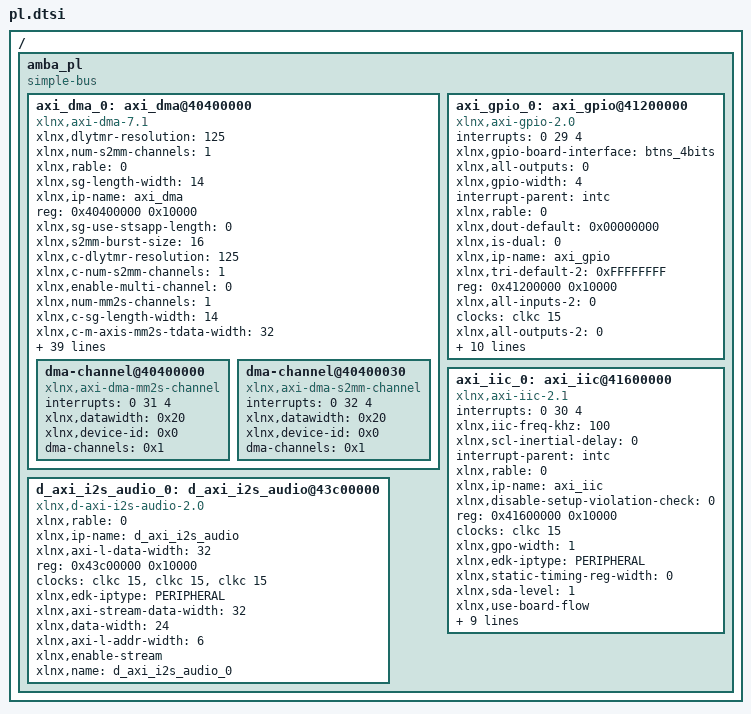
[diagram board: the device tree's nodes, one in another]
/ {
	amba_pl: amba_pl {
		ranges;
		compatible = "simple-bus";
		#address-cells = <1>;
		#size-cells = <1>;
		axi_dma_0: axi_dma@40400000 {
			xlnx,dlytmr-resolution = <125>;
			xlnx,num-s2mm-channels = <1>;
			xlnx,rable = <0>;
			xlnx,sg-length-width = <14>;
			xlnx,ip-name = "axi_dma";
			reg = <0x40400000 0x10000>;
			xlnx,sg-use-stsapp-length = <0>;
			xlnx,s2mm-burst-size = <16>;
			xlnx,c-dlytmr-resolution = <125>;
			xlnx,c-num-s2mm-channels = <1>;
			xlnx,enable-multi-channel = <0>;
			xlnx,num-mm2s-channels = <1>;
			xlnx,c-sg-length-width = <14>;
			interrupt-names = "mm2s_introut" , "s2mm_introut";
			compatible = "xlnx,axi-dma-7.1" , "xlnx,axi-dma-1.00.a";
			xlnx,c-m-axis-mm2s-tdata-width = <32>;
			xlnx,c-sg-use-stsapp-length = <0>;
			xlnx,c-s2mm-burst-size = <16>;
			xlnx,mm2s-burst-size = <16>;
			xlnx,c-enable-multi-channel = <0>;
			xlnx,c-num-mm2s-channels = <1>;
			interrupt-parent = <&intc>;
			xlnx,include-s2mm-dre = <0>;
			xlnx,c-mm2s-burst-size = <16>;
			status = "okay";
			xlnx,c-include-s2mm-dre = <0>;
			xlnx,include-mm2s-dre = <0>;
			xlnx,name = "axi_dma_0";
			interrupts = < 0 31 4 0 32 4 >;
			xlnx,c-include-sg = <0>;
			xlnx,c-m-axi-s2mm-data-width = <32>;
			xlnx,include-s2mm-sf = <1>;
			xlnx,c-include-mm2s-dre = <0>;
			xlnx,include-s2mm = <1>;
			clocks = <&clkc 15>, <&clkc 15>, <&clkc 15>;
			xlnx,addrwidth = <0x20>;
			xlnx,c-m-axi-mm2s-data-width = <32>;
			xlnx,edk-iptype = "PERIPHERAL";
			xlnx,c-include-s2mm-sf = <1>;
			xlnx,include-mm2s-sf = <1>;
			clock-names = "m_axi_mm2s_aclk" , "m_axi_s2mm_aclk" , "s_axi_lite_aclk";
			xlnx,c-include-s2mm = <1>;
			xlnx,c-addr-width = <32>;
			xlnx,c-single-interface = <0>;
			xlnx,include-mm2s = <1>;
			xlnx,c-s-axis-s2mm-tdata-width = <32>;
			xlnx,s2mm-data-width = <0x20>;
			xlnx,c-include-mm2s-sf = <1>;
			xlnx,prmry-is-aclk-async = <0>;
			xlnx,c-include-mm2s = <1>;
			xlnx,increase-throughput = <0>;
			xlnx,micro-dma = <0>;
			xlnx,mm2s-data-width = <0x20>;
			xlnx,c-prmry-is-aclk-async = <0>;
			xlnx,c-sg-include-stscntrl-strm = <0>;
			xlnx,c-increase-throughput = <0>;
			xlnx,c-micro-dma = <0>;
			dma-channel@40400000 {
				interrupts = <0 31 4>;
				xlnx,datawidth = <0x20>;
				xlnx,device-id = <0x0>;
				compatible = "xlnx,axi-dma-mm2s-channel";
				dma-channels = <0x1>;
			};
			dma-channel@40400030 {
				interrupts = <0 32 4>;
				xlnx,datawidth = <0x20>;
				xlnx,device-id = <0x0>;
				compatible = "xlnx,axi-dma-s2mm-channel";
				dma-channels = <0x1>;
			};
		};
		axi_gpio_0: axi_gpio@41200000 {
			#interrupt-cells = <2>;
			interrupts = < 0 29 4 >;
			xlnx,gpio-board-interface = "btns_4bits";
			compatible = "xlnx,axi-gpio-2.0" , "xlnx,xps-gpio-1.00.a";
			xlnx,all-outputs = <0>;
			xlnx,gpio-width = <4>;
			interrupt-parent = <&intc>;
			xlnx,rable = <0>;
			xlnx,dout-default = <0x00000000>;
			xlnx,is-dual = <0>;
			xlnx,ip-name = "axi_gpio";
			xlnx,tri-default-2 = <0xFFFFFFFF>;
			reg = <0x41200000 0x10000>;
			xlnx,all-inputs-2 = <0>;
			clocks = <&clkc 15>;
			xlnx,all-outputs-2 = <0>;
			xlnx,interrupt-present = <1>;
			xlnx,gpio2-board-interface = "Custom";
			xlnx,edk-iptype = "PERIPHERAL";
			xlnx,dout-default-2 = <0x00000000>;
			xlnx,gpio2-width = <32>;
			status = "okay";
			clock-names = "s_axi_aclk";
			xlnx,use-board-flow;
			interrupt-controller;
			interrupt-names = "ip2intc_irpt";
			xlnx,tri-default = <0xFFFFFFFF>;
			xlnx,name = "axi_gpio_0";
			xlnx,all-inputs = <1>;
		};
		axi_iic_0: axi_iic@41600000 {
			interrupts = < 0 30 4 >;
			xlnx,iic-freq-khz = <100>;
			compatible = "xlnx,axi-iic-2.1" , "xlnx,xps-iic-2.00.a";
			xlnx,scl-inertial-delay = <0>;
			interrupt-parent = <&intc>;
			xlnx,rable = <0>;
			xlnx,ip-name = "axi_iic";
			xlnx,disable-setup-violation-check = <0>;
			reg = <0x41600000 0x10000>;
			clocks = <&clkc 15>;
			xlnx,gpo-width = <1>;
			xlnx,edk-iptype = "PERIPHERAL";
			xlnx,static-timing-reg-width = <0>;
			xlnx,sda-level = <1>;
			status = "okay";
			clock-names = "s_axi_aclk";
			xlnx,use-board-flow;
			xlnx,ten-bit-adr = <0>;
			xlnx,default-value = <0x00>;
			interrupt-names = "iic2intc_irpt";
			xlnx,timing-reg-width = <32>;
			xlnx,iic-board-interface = "Custom";
			xlnx,iic-freq = <100000>;
			xlnx,smbus-pmbus-host = <0>;
			xlnx,sda-inertial-delay = <0>;
			xlnx,name = "axi_iic_0";
			xlnx,axi-aclk-freq-mhz = <100>;
		};
		d_axi_i2s_audio_0: d_axi_i2s_audio@43c00000 {
			compatible = "xlnx,d-axi-i2s-audio-2.0";
			xlnx,rable = <0>;
			xlnx,ip-name = "d_axi_i2s_audio";
			xlnx,axi-l-data-width = <32>;
			reg = <0x43c00000 0x10000>;
			clocks = <&clkc 15>, <&clkc 15>, <&clkc 15>;
			xlnx,edk-iptype = "PERIPHERAL";
			status = "okay";
			clock-names = "AXI_L_aclk" , "M_AXIS_S2MM_ACLK" , "S_AXIS_MM2S_ACLK";
			xlnx,axi-stream-data-width = <32>;
			xlnx,data-width = <24>;
			xlnx,axi-l-addr-width = <6>;
			xlnx,enable-stream;
			xlnx,name = "d_axi_i2s_audio_0";
		};
	};
};
